# f29h85x_hsm_dthe_regs register map
Vendor: Texas Instruments
Peripheral module from a debugger description file (folder HSM).
Registers are 32-bit, read-only, no defined reset value unless marked. A register's access mark holds for its fields unless they carry their own. Offsets are as the file gives them; lines under a group give offsets from that group; [hi:lo] are bit positions; {n}, {i} and the like mark numbered series; 'fields as' and 'values as' point back to an identical list; <NAME> marks a mode.

## HSM_DTHE — HSM DTHE Registers
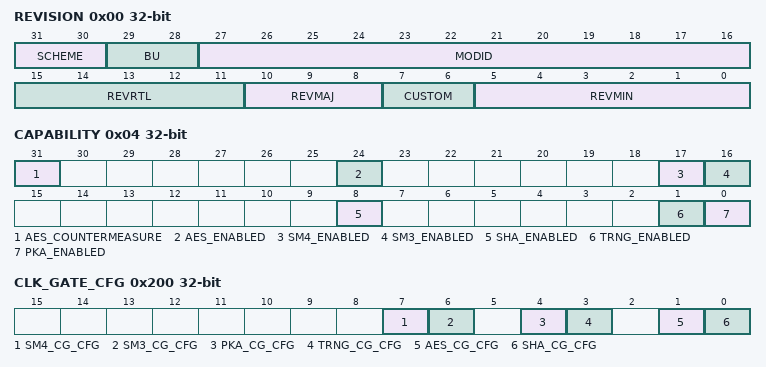
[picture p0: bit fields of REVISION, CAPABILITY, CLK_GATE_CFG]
0x00 REVISION
  [31:30] SCHEME, [29:28] BU, [27:16] MODID, [15:11] REVRTL, [10:8] REVMAJ, [7:6] CUSTOM, [5:0] REVMIN
0x04 CAPABILITY
  [31] AES_COUNTERMEASURE, [24] AES_ENABLED, [17] SM4_ENABLED, [16] SM3_ENABLED, [8] SHA_ENABLED, [1] TRNG_ENABLED, [0] PKA_ENABLED
0x200 CLK_GATE_CFG rw
  [7] SM4_CG_CFG, [6] SM3_CG_CFG, [4] PKA_CG_CFG, [3] TRNG_CG_CFG, [1] AES_CG_CFG, [0] SHA_CG_CFG
